# MSS_CTRL register map
Vendor: Texas Instruments
Registers are 32-bit, read-only, no defined reset value unless marked. A register's access mark holds for its fields unless they carry their own. Offsets are as the file gives them; [hi:lo] are bit positions; {n}, {i} and the like mark numbered series; 'fields as' and 'values as' point back to an identical list.

## MSS_CTRL (part 2 of 3)
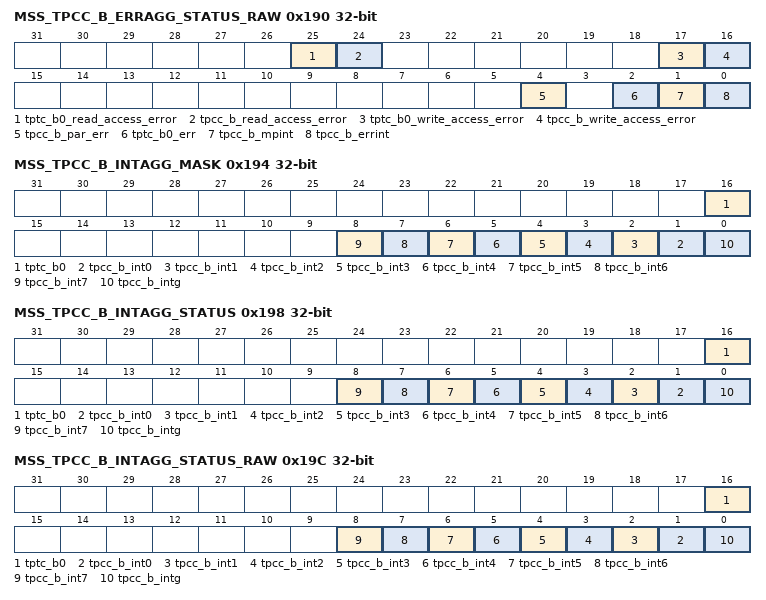
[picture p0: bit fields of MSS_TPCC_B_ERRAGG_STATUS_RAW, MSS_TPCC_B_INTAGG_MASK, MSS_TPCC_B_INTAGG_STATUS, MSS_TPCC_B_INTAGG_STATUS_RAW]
0x190 MSS_TPCC_B_ERRAGG_STATUS_RAW rw
  [25] tptc_b0_read_access_error — Raw Status of Error from MSS_TPTC_B0. Set irrespective if the Interupt is masked or unmasked in MSS_TPCC_B_ERRAGG_MASK
  [24] tpcc_b_read_access_error — Raw Status of Error from MSS_TPCC_B. Set irrespective if the Interupt is masked or unmasked in MSS_TPCC_B_ERRAGG_MASK
  [17] tptc_b0_write_access_error — Raw Status of Error from MSS_TPTC_B0. Set irrespective if the Interupt is masked or unmasked in MSS_TPCC_B_ERRAGG_MASK
  [16] tpcc_b_write_access_error — Raw Status of Error from MSS_TPCC_B. Set irrespective if the Interupt is masked or unmasked in MSS_TPCC_B_ERRAGG_MASK
  [4] tpcc_b_par_err — Raw Status of Error from MSS_TPCC_B. Set irrespective if the Interupt is masked or unmasked in MSS_TPCC_B_ERRAGG_MASK
  [2] tptc_b0_err — Raw Status of Error from MSS_TPTC_B0. Set irrespective if the Interupt is masked or unmasked in MSS_TPCC_B_ERRAGG_MASK
  [1] tpcc_b_mpint — Raw Status of Error from MSS_TPCC_B. Set irrespective if the Interupt is masked or unmasked in MSS_TPCC_B_ERRAGG_MASK
  [0] tpcc_b_errint — Raw Status of Error from MSS_TPCC_B. Set irrespective if the Interupt is masked or unmasked in MSS_TPCC_B_ERRAGG_MASK
0x194 MSS_TPCC_B_INTAGG_MASK rw
  [16] tptc_b0 — Mask Interrupt from TPTC A0 to aggregated Interrupt MSS_TPCC_A_INTAGG 1 : Interrupt is Masked 0 : Interrupt is Unmasked
  [n+1] tpcc_b_int{n} (n=0..7) — Mask Interrupt from MSS_TPCC_B to aggregated Interrupt MSS_TPCC_B_INTAGG 1 : Interrupt is Masked 0 : Interrupt is Unmasked
  [0] tpcc_b_intg — Mask Interrupt from MSS_TPCC_B to aggregated Interrupt MSS_TPCC_B_INTAGG 1 : Interrupt is Masked 0 : Interrupt is Unmasked
0x198 MSS_TPCC_B_INTAGG_STATUS rw
  [16] tptc_b0 — Status of Interrupt from TPTC A0. Set only if Interupt is unmasked in MSS_TPCC_A_INTAGG_MASK Wrie 0x1 to clear this interrupt.
  [n+1] tpcc_b_int{n} (n=0..7) — Status of Interrupt from MSS_TPCC_B. Set only if Interupt is unmasked in MSS_TPCC_B_INTAGG_MASK Wrie 0x1 to clear this interrupt.
  [0] tpcc_b_intg — Status of Interrupt from MSS_TPCC_B. Set only if Interupt is unmasked in MSS_TPCC_B_INTAGG_MASK Wrie 0x1 to clear this interrupt.
0x19C MSS_TPCC_B_INTAGG_STATUS_RAW rw
  [16] tptc_b0 — Raw Status of Interrupt from TPTC A0. Set irrespective if the Interupt is masked or unmasked in MSS_TPCC_A_INTAGG_MASK
  [n+1] tpcc_b_int{n} (n=0..7) — Raw Status of Interrupt from MSS_TPCC_B. Set irrespective if the Interupt is masked or unmasked in MSS_TPCC_C_INTAGG_MASK
  [0] tpcc_b_intg — Raw Status of Interrupt from MSS_TPCC_B. Set irrespective if the Interupt is masked or unmasked in MSS_TPCC_C_INTAGG_MASK
0x1A0 MSS_BUS_SAFETY_CTRL rw
  [2:0] enable — Refer to TPR12 Substem Microarch document for more details
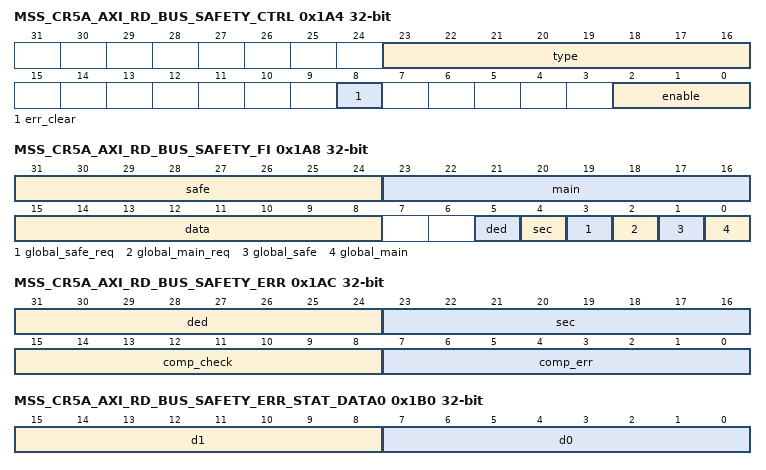
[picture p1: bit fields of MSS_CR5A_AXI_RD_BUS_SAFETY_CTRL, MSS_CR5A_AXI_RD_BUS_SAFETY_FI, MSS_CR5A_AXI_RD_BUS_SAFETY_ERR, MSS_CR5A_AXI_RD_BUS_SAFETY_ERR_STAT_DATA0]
0x1A4 MSS_CR5A_AXI_RD_BUS_SAFETY_CTRL access per field
  [23:16] type ro — Refer to TPR12 Substem Microarch document for more details
  [8] err_clear rw — Refer to TPR12 Substem Microarch document for more details
  [2:0] enable rw — Refer to TPR12 Substem Microarch document for more details
0x1A8 MSS_CR5A_AXI_RD_BUS_SAFETY_FI rw
  [31:24] safe — Refer to TPR12 Substem Microarch document for more details
  [23:16] main — Refer to TPR12 Substem Microarch document for more details
  [15:8] data — Refer to TPR12 Substem Microarch document for more details
  [5] ded — Refer to TPR12 Substem Microarch document for more details
  [4] sec — Refer to TPR12 Substem Microarch document for more details
  [3] global_safe_req — Refer to TPR12 Substem Microarch document for more details
  [2] global_main_req — Refer to TPR12 Substem Microarch document for more details
  [1] global_safe — Refer to TPR12 Substem Microarch document for more details
  [0] global_main — Refer to TPR12 Substem Microarch document for more details
0x1AC MSS_CR5A_AXI_RD_BUS_SAFETY_ERR
  [31:24] ded — Refer to TPR12 Substem Microarch document for more details
  [23:16] sec — Refer to TPR12 Substem Microarch document for more details
  [15:8] comp_check — Refer to TPR12 Substem Microarch document for more details
  [7:0] comp_err — Refer to TPR12 Substem Microarch document for more details
0x1B0 MSS_CR5A_AXI_RD_BUS_SAFETY_ERR_STAT_DATA0
  [15:8] d1 — Refer to TPR12 Substem Microarch document for more details
  [7:0] d0 — Refer to TPR12 Substem Microarch document for more details
0x1B4 MSS_CR5A_AXI_RD_BUS_SAFETY_ERR_STAT_CMD
  [31:0] stat — Refer to TPR12 Substem Microarch document for more details
0x1B8 MSS_CR5A_AXI_RD_BUS_SAFETY_ERR_STAT_READ
  fields as MSS_CR5A_AXI_RD_BUS_SAFETY_ERR_STAT_CMD
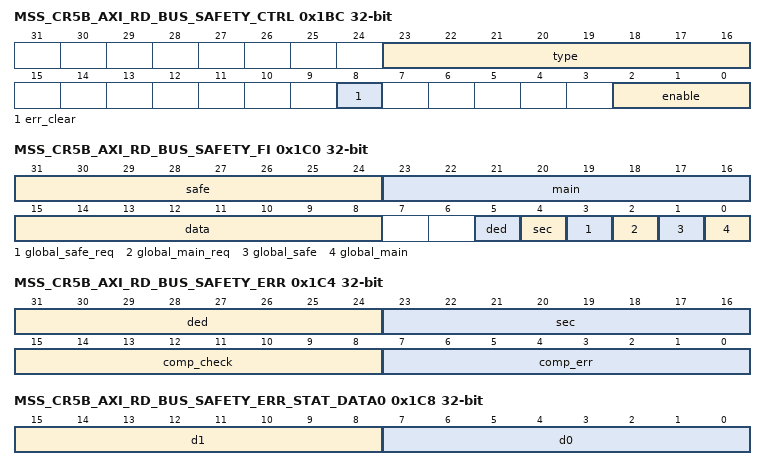
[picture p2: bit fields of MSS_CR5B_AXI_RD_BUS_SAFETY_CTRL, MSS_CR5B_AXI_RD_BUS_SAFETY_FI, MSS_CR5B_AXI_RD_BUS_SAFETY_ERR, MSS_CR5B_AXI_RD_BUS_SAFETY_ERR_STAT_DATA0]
0x1BC MSS_CR5B_AXI_RD_BUS_SAFETY_CTRL access per field
  fields as MSS_CR5A_AXI_RD_BUS_SAFETY_CTRL
0x1C0 MSS_CR5B_AXI_RD_BUS_SAFETY_FI rw
  fields as MSS_CR5A_AXI_RD_BUS_SAFETY_FI
0x1C4 MSS_CR5B_AXI_RD_BUS_SAFETY_ERR
  fields as MSS_CR5A_AXI_RD_BUS_SAFETY_ERR
0x1C8 MSS_CR5B_AXI_RD_BUS_SAFETY_ERR_STAT_DATA0
  fields as MSS_CR5A_AXI_RD_BUS_SAFETY_ERR_STAT_DATA0
0x1CC MSS_CR5B_AXI_RD_BUS_SAFETY_ERR_STAT_CMD
  fields as MSS_CR5A_AXI_RD_BUS_SAFETY_ERR_STAT_CMD
0x1D0 MSS_CR5B_AXI_RD_BUS_SAFETY_ERR_STAT_READ
  fields as MSS_CR5A_AXI_RD_BUS_SAFETY_ERR_STAT_CMD
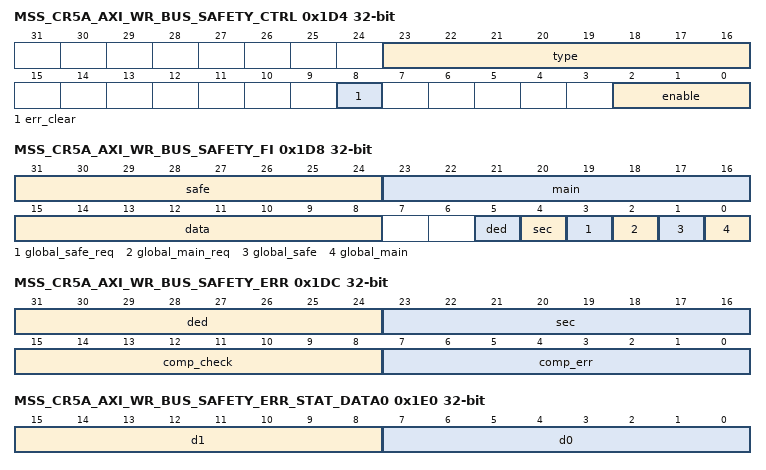
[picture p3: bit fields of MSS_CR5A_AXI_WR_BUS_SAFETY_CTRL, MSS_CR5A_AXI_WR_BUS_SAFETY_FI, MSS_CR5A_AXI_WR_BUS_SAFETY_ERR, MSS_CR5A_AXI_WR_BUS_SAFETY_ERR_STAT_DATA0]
0x1D4 MSS_CR5A_AXI_WR_BUS_SAFETY_CTRL access per field
  fields as MSS_CR5A_AXI_RD_BUS_SAFETY_CTRL
0x1D8 MSS_CR5A_AXI_WR_BUS_SAFETY_FI rw
  fields as MSS_CR5A_AXI_RD_BUS_SAFETY_FI
0x1DC MSS_CR5A_AXI_WR_BUS_SAFETY_ERR
  fields as MSS_CR5A_AXI_RD_BUS_SAFETY_ERR
0x1E0 MSS_CR5A_AXI_WR_BUS_SAFETY_ERR_STAT_DATA0
  fields as MSS_CR5A_AXI_RD_BUS_SAFETY_ERR_STAT_DATA0
0x1E4 MSS_CR5A_AXI_WR_BUS_SAFETY_ERR_STAT_CMD
  fields as MSS_CR5A_AXI_RD_BUS_SAFETY_ERR_STAT_CMD
0x1E8 MSS_CR5A_AXI_WR_BUS_SAFETY_ERR_STAT_WRITE
  fields as MSS_CR5A_AXI_RD_BUS_SAFETY_ERR_STAT_CMD
0x1EC MSS_CR5A_AXI_WR_BUS_SAFETY_ERR_STAT_WRITERESP
  fields as MSS_CR5A_AXI_RD_BUS_SAFETY_ERR_STAT_CMD
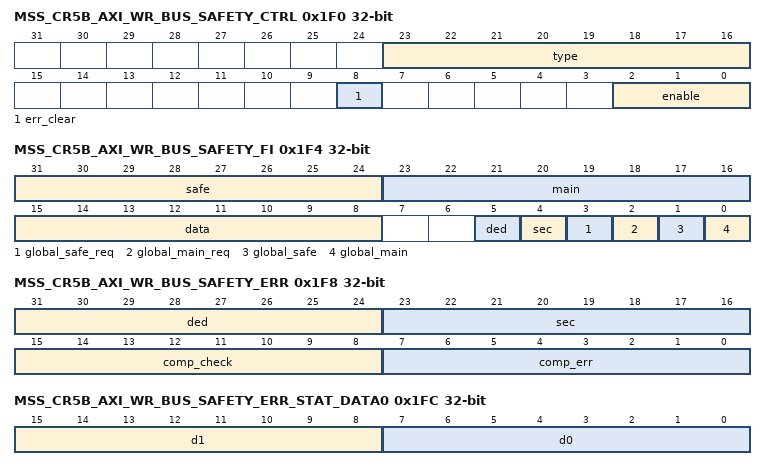
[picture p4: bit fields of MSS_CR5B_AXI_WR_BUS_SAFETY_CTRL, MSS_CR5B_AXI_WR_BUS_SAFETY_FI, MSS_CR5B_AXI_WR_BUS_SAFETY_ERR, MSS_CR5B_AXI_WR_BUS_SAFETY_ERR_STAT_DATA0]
0x1F0 MSS_CR5B_AXI_WR_BUS_SAFETY_CTRL access per field
  fields as MSS_CR5A_AXI_RD_BUS_SAFETY_CTRL
0x1F4 MSS_CR5B_AXI_WR_BUS_SAFETY_FI rw
  fields as MSS_CR5A_AXI_RD_BUS_SAFETY_FI
0x1F8 MSS_CR5B_AXI_WR_BUS_SAFETY_ERR
  fields as MSS_CR5A_AXI_RD_BUS_SAFETY_ERR
0x1FC MSS_CR5B_AXI_WR_BUS_SAFETY_ERR_STAT_DATA0
  fields as MSS_CR5A_AXI_RD_BUS_SAFETY_ERR_STAT_DATA0
0x200 MSS_CR5B_AXI_WR_BUS_SAFETY_ERR_STAT_CMD
  fields as MSS_CR5A_AXI_RD_BUS_SAFETY_ERR_STAT_CMD
0x204 MSS_CR5B_AXI_WR_BUS_SAFETY_ERR_STAT_WRITE
  fields as MSS_CR5A_AXI_RD_BUS_SAFETY_ERR_STAT_CMD
0x208 MSS_CR5B_AXI_WR_BUS_SAFETY_ERR_STAT_WRITERESP
  fields as MSS_CR5A_AXI_RD_BUS_SAFETY_ERR_STAT_CMD
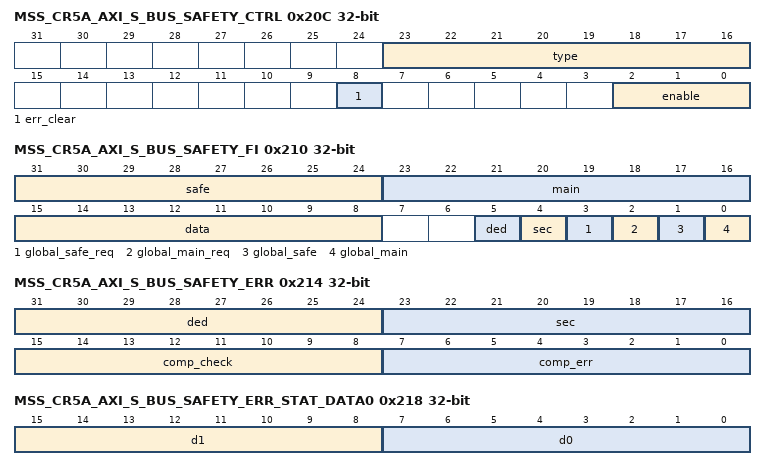
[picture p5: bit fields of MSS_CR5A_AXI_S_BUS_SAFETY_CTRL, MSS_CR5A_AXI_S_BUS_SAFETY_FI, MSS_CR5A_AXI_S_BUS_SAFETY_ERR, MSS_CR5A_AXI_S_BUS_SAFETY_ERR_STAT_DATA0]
0x20C MSS_CR5A_AXI_S_BUS_SAFETY_CTRL access per field
  fields as MSS_CR5A_AXI_RD_BUS_SAFETY_CTRL
0x210 MSS_CR5A_AXI_S_BUS_SAFETY_FI rw
  fields as MSS_CR5A_AXI_RD_BUS_SAFETY_FI
0x214 MSS_CR5A_AXI_S_BUS_SAFETY_ERR
  fields as MSS_CR5A_AXI_RD_BUS_SAFETY_ERR
0x218 MSS_CR5A_AXI_S_BUS_SAFETY_ERR_STAT_DATA0
  fields as MSS_CR5A_AXI_RD_BUS_SAFETY_ERR_STAT_DATA0
0x21C MSS_CR5A_AXI_S_BUS_SAFETY_ERR_STAT_CMD
  fields as MSS_CR5A_AXI_RD_BUS_SAFETY_ERR_STAT_CMD
0x220 MSS_CR5A_AXI_S_BUS_SAFETY_ERR_STAT_WRITE
  fields as MSS_CR5A_AXI_RD_BUS_SAFETY_ERR_STAT_CMD
0x224 MSS_CR5A_AXI_S_BUS_SAFETY_ERR_STAT_READ
  fields as MSS_CR5A_AXI_RD_BUS_SAFETY_ERR_STAT_CMD
0x228 MSS_CR5A_AXI_S_BUS_SAFETY_ERR_STAT_WRITERESP
  fields as MSS_CR5A_AXI_RD_BUS_SAFETY_ERR_STAT_CMD
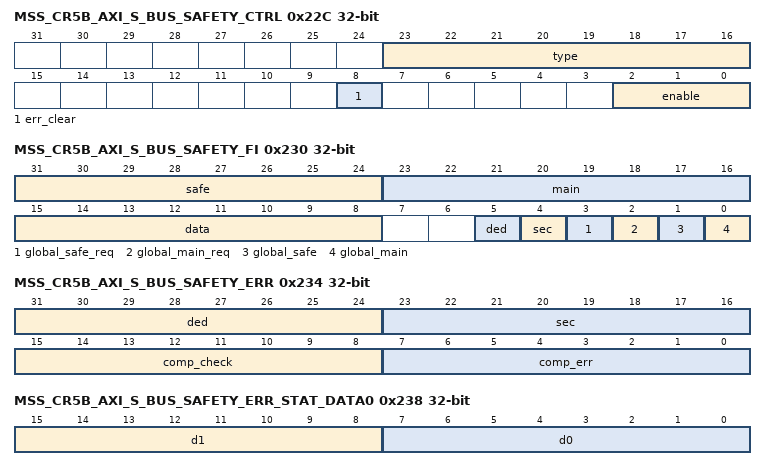
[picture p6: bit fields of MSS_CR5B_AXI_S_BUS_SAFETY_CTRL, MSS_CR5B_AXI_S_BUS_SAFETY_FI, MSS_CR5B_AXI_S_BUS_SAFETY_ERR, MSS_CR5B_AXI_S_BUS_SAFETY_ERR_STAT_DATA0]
0x22C MSS_CR5B_AXI_S_BUS_SAFETY_CTRL access per field
  fields as MSS_CR5A_AXI_RD_BUS_SAFETY_CTRL
0x230 MSS_CR5B_AXI_S_BUS_SAFETY_FI rw
  fields as MSS_CR5A_AXI_RD_BUS_SAFETY_FI
0x234 MSS_CR5B_AXI_S_BUS_SAFETY_ERR
  fields as MSS_CR5A_AXI_RD_BUS_SAFETY_ERR
0x238 MSS_CR5B_AXI_S_BUS_SAFETY_ERR_STAT_DATA0
  fields as MSS_CR5A_AXI_RD_BUS_SAFETY_ERR_STAT_DATA0
0x23C MSS_CR5B_AXI_S_BUS_SAFETY_ERR_STAT_CMD
  fields as MSS_CR5A_AXI_RD_BUS_SAFETY_ERR_STAT_CMD
0x240 MSS_CR5B_AXI_S_BUS_SAFETY_ERR_STAT_WRITE
  fields as MSS_CR5A_AXI_RD_BUS_SAFETY_ERR_STAT_CMD
0x244 MSS_CR5B_AXI_S_BUS_SAFETY_ERR_STAT_READ
  fields as MSS_CR5A_AXI_RD_BUS_SAFETY_ERR_STAT_CMD
0x248 MSS_CR5B_AXI_S_BUS_SAFETY_ERR_STAT_WRITERESP
  fields as MSS_CR5A_AXI_RD_BUS_SAFETY_ERR_STAT_CMD
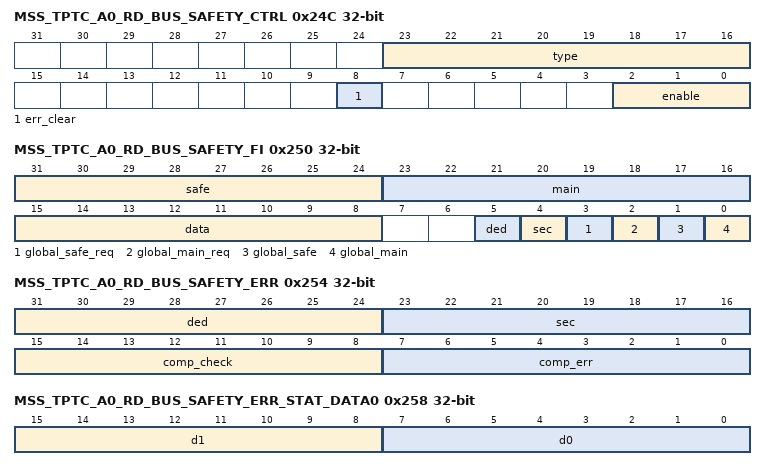
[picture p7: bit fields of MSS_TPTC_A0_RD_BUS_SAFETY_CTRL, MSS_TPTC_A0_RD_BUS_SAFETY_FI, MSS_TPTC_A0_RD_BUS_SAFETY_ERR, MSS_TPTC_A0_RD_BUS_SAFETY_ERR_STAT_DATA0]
0x24C MSS_TPTC_A0_RD_BUS_SAFETY_CTRL access per field
  fields as MSS_CR5A_AXI_RD_BUS_SAFETY_CTRL
0x250 MSS_TPTC_A0_RD_BUS_SAFETY_FI rw
  fields as MSS_CR5A_AXI_RD_BUS_SAFETY_FI
0x254 MSS_TPTC_A0_RD_BUS_SAFETY_ERR
  fields as MSS_CR5A_AXI_RD_BUS_SAFETY_ERR
0x258 MSS_TPTC_A0_RD_BUS_SAFETY_ERR_STAT_DATA0
  fields as MSS_CR5A_AXI_RD_BUS_SAFETY_ERR_STAT_DATA0
0x25C MSS_TPTC_A0_RD_BUS_SAFETY_ERR_STAT_CMD
  fields as MSS_CR5A_AXI_RD_BUS_SAFETY_ERR_STAT_CMD
0x260 MSS_TPTC_A0_RD_BUS_SAFETY_ERR_STAT_READ
  fields as MSS_CR5A_AXI_RD_BUS_SAFETY_ERR_STAT_CMD
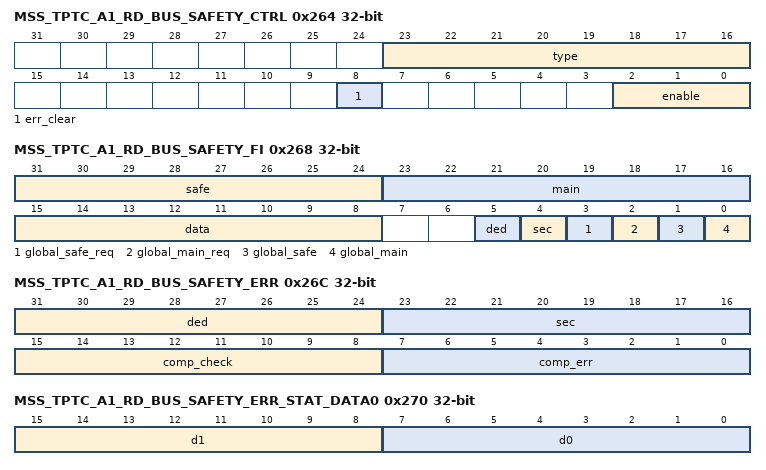
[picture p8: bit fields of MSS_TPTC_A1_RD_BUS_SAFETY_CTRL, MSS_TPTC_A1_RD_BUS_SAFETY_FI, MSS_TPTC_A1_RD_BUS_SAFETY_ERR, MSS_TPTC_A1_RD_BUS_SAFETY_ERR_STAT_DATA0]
0x264 MSS_TPTC_A1_RD_BUS_SAFETY_CTRL access per field
  fields as MSS_CR5A_AXI_RD_BUS_SAFETY_CTRL
0x268 MSS_TPTC_A1_RD_BUS_SAFETY_FI rw
  fields as MSS_CR5A_AXI_RD_BUS_SAFETY_FI
0x26C MSS_TPTC_A1_RD_BUS_SAFETY_ERR
  fields as MSS_CR5A_AXI_RD_BUS_SAFETY_ERR
0x270 MSS_TPTC_A1_RD_BUS_SAFETY_ERR_STAT_DATA0
  fields as MSS_CR5A_AXI_RD_BUS_SAFETY_ERR_STAT_DATA0
0x274 MSS_TPTC_A1_RD_BUS_SAFETY_ERR_STAT_CMD
  fields as MSS_CR5A_AXI_RD_BUS_SAFETY_ERR_STAT_CMD
0x278 MSS_TPTC_A1_RD_BUS_SAFETY_ERR_STAT_READ
  fields as MSS_CR5A_AXI_RD_BUS_SAFETY_ERR_STAT_CMD
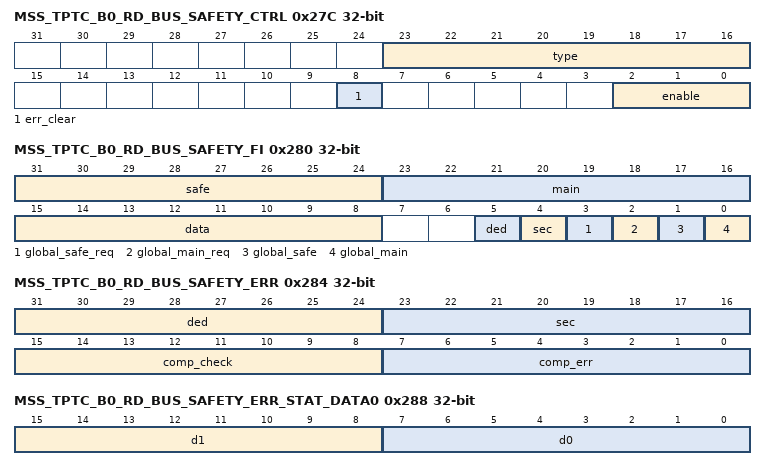
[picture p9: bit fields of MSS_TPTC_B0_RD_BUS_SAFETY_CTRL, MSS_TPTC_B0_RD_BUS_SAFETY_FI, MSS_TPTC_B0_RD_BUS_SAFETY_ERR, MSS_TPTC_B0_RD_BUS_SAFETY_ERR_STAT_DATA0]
0x27C MSS_TPTC_B0_RD_BUS_SAFETY_CTRL access per field
  fields as MSS_CR5A_AXI_RD_BUS_SAFETY_CTRL
0x280 MSS_TPTC_B0_RD_BUS_SAFETY_FI rw
  fields as MSS_CR5A_AXI_RD_BUS_SAFETY_FI
0x284 MSS_TPTC_B0_RD_BUS_SAFETY_ERR
  fields as MSS_CR5A_AXI_RD_BUS_SAFETY_ERR
0x288 MSS_TPTC_B0_RD_BUS_SAFETY_ERR_STAT_DATA0
  fields as MSS_CR5A_AXI_RD_BUS_SAFETY_ERR_STAT_DATA0
0x28C MSS_TPTC_B0_RD_BUS_SAFETY_ERR_STAT_CMD
  fields as MSS_CR5A_AXI_RD_BUS_SAFETY_ERR_STAT_CMD
0x290 MSS_TPTC_B0_RD_BUS_SAFETY_ERR_STAT_READ
  fields as MSS_CR5A_AXI_RD_BUS_SAFETY_ERR_STAT_CMD
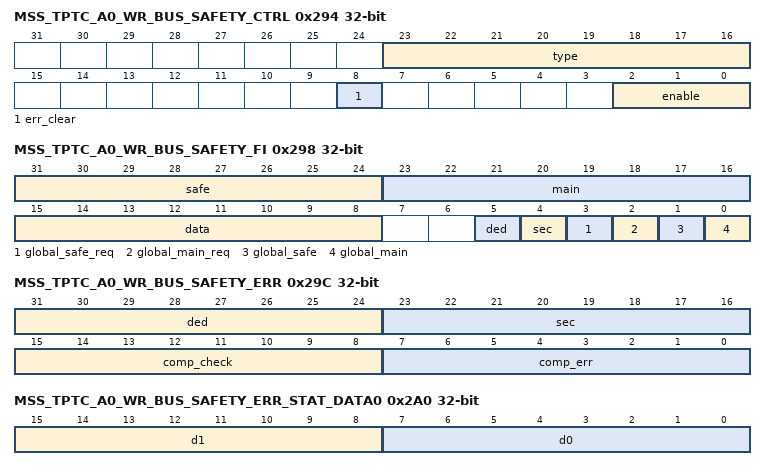
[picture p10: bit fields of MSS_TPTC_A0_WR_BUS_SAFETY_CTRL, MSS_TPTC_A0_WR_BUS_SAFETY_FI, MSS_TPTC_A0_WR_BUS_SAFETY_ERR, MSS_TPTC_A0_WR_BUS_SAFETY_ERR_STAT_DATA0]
0x294 MSS_TPTC_A0_WR_BUS_SAFETY_CTRL access per field
  fields as MSS_CR5A_AXI_RD_BUS_SAFETY_CTRL
0x298 MSS_TPTC_A0_WR_BUS_SAFETY_FI rw
  fields as MSS_CR5A_AXI_RD_BUS_SAFETY_FI
0x29C MSS_TPTC_A0_WR_BUS_SAFETY_ERR
  fields as MSS_CR5A_AXI_RD_BUS_SAFETY_ERR
0x2A0 MSS_TPTC_A0_WR_BUS_SAFETY_ERR_STAT_DATA0
  fields as MSS_CR5A_AXI_RD_BUS_SAFETY_ERR_STAT_DATA0
0x2A4 MSS_TPTC_A0_WR_BUS_SAFETY_ERR_STAT_CMD
  fields as MSS_CR5A_AXI_RD_BUS_SAFETY_ERR_STAT_CMD
0x2A8 MSS_TPTC_A0_WR_BUS_SAFETY_ERR_STAT_WRITE
  fields as MSS_CR5A_AXI_RD_BUS_SAFETY_ERR_STAT_CMD
0x2AC MSS_TPTC_A0_WR_BUS_SAFETY_ERR_STAT_WRITERESP
  fields as MSS_CR5A_AXI_RD_BUS_SAFETY_ERR_STAT_CMD
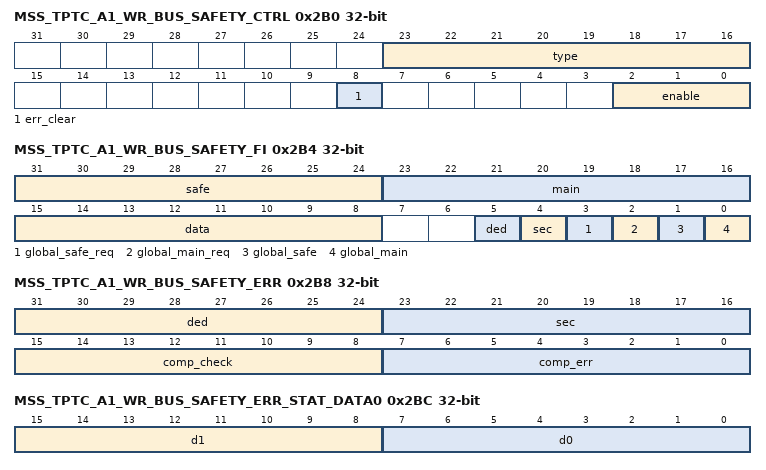
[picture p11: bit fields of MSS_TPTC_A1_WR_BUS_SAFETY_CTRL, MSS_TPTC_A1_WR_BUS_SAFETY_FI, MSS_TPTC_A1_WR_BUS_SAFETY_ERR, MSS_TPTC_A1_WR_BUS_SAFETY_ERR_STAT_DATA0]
0x2B0 MSS_TPTC_A1_WR_BUS_SAFETY_CTRL access per field
  fields as MSS_CR5A_AXI_RD_BUS_SAFETY_CTRL
0x2B4 MSS_TPTC_A1_WR_BUS_SAFETY_FI rw
  fields as MSS_CR5A_AXI_RD_BUS_SAFETY_FI
0x2B8 MSS_TPTC_A1_WR_BUS_SAFETY_ERR
  fields as MSS_CR5A_AXI_RD_BUS_SAFETY_ERR
0x2BC MSS_TPTC_A1_WR_BUS_SAFETY_ERR_STAT_DATA0
  fields as MSS_CR5A_AXI_RD_BUS_SAFETY_ERR_STAT_DATA0
0x2C0 MSS_TPTC_A1_WR_BUS_SAFETY_ERR_STAT_CMD
  fields as MSS_CR5A_AXI_RD_BUS_SAFETY_ERR_STAT_CMD
0x2C4 MSS_TPTC_A1_WR_BUS_SAFETY_ERR_STAT_WRITE
  fields as MSS_CR5A_AXI_RD_BUS_SAFETY_ERR_STAT_CMD
0x2C8 MSS_TPTC_A1_WR_BUS_SAFETY_ERR_STAT_WRITERESP
  fields as MSS_CR5A_AXI_RD_BUS_SAFETY_ERR_STAT_CMD
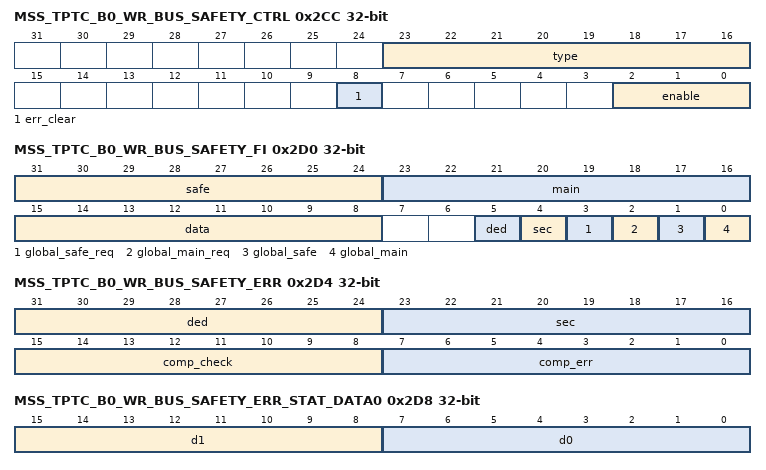
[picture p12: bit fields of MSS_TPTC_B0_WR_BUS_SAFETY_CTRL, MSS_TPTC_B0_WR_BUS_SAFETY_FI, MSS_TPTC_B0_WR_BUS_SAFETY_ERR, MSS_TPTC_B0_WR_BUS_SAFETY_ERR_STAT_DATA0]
0x2CC MSS_TPTC_B0_WR_BUS_SAFETY_CTRL access per field
  fields as MSS_CR5A_AXI_RD_BUS_SAFETY_CTRL
0x2D0 MSS_TPTC_B0_WR_BUS_SAFETY_FI rw
  fields as MSS_CR5A_AXI_RD_BUS_SAFETY_FI
0x2D4 MSS_TPTC_B0_WR_BUS_SAFETY_ERR
  fields as MSS_CR5A_AXI_RD_BUS_SAFETY_ERR
0x2D8 MSS_TPTC_B0_WR_BUS_SAFETY_ERR_STAT_DATA0
  fields as MSS_CR5A_AXI_RD_BUS_SAFETY_ERR_STAT_DATA0
0x2DC MSS_TPTC_B0_WR_BUS_SAFETY_ERR_STAT_CMD
  fields as MSS_CR5A_AXI_RD_BUS_SAFETY_ERR_STAT_CMD
0x2E0 MSS_TPTC_B0_WR_BUS_SAFETY_ERR_STAT_WRITE
  fields as MSS_CR5A_AXI_RD_BUS_SAFETY_ERR_STAT_CMD
0x2E4 MSS_TPTC_B0_WR_BUS_SAFETY_ERR_STAT_WRITERESP
  fields as MSS_CR5A_AXI_RD_BUS_SAFETY_ERR_STAT_CMD
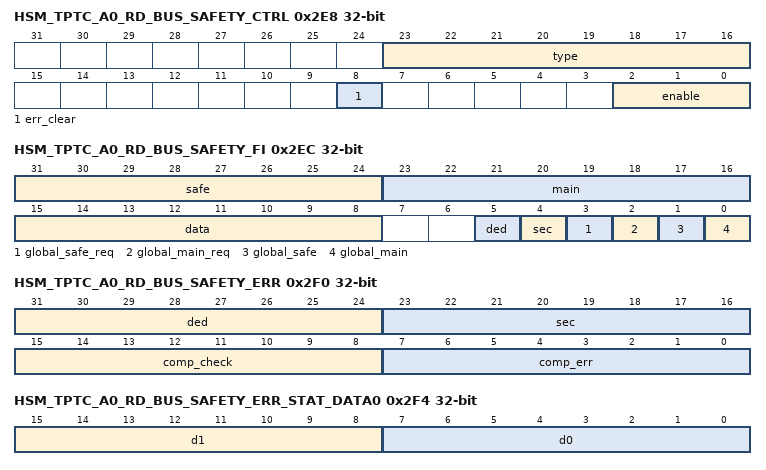
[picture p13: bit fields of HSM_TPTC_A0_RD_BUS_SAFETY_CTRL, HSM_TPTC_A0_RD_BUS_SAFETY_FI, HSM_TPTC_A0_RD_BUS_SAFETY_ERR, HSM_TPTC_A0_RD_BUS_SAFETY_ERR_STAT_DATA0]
0x2E8 HSM_TPTC_A0_RD_BUS_SAFETY_CTRL access per field
  fields as MSS_CR5A_AXI_RD_BUS_SAFETY_CTRL
0x2EC HSM_TPTC_A0_RD_BUS_SAFETY_FI rw
  fields as MSS_CR5A_AXI_RD_BUS_SAFETY_FI
0x2F0 HSM_TPTC_A0_RD_BUS_SAFETY_ERR
  fields as MSS_CR5A_AXI_RD_BUS_SAFETY_ERR
0x2F4 HSM_TPTC_A0_RD_BUS_SAFETY_ERR_STAT_DATA0
  fields as MSS_CR5A_AXI_RD_BUS_SAFETY_ERR_STAT_DATA0
0x2F8 HSM_TPTC_A0_RD_BUS_SAFETY_ERR_STAT_CMD
  fields as MSS_CR5A_AXI_RD_BUS_SAFETY_ERR_STAT_CMD
0x2FC HSM_TPTC_A0_RD_BUS_SAFETY_ERR_STAT_READ
  fields as MSS_CR5A_AXI_RD_BUS_SAFETY_ERR_STAT_CMD
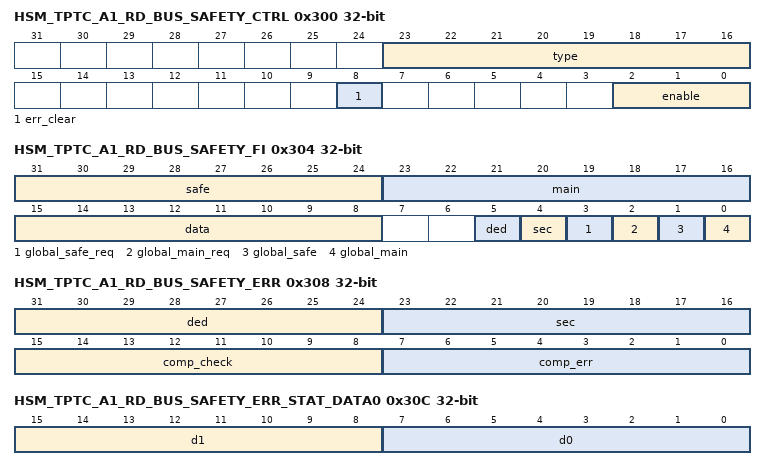
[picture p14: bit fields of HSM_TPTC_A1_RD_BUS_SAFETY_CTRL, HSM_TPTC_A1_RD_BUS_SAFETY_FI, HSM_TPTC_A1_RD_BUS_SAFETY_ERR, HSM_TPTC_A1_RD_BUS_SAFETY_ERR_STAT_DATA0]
0x300 HSM_TPTC_A1_RD_BUS_SAFETY_CTRL access per field
  fields as MSS_CR5A_AXI_RD_BUS_SAFETY_CTRL
0x304 HSM_TPTC_A1_RD_BUS_SAFETY_FI rw
  fields as MSS_CR5A_AXI_RD_BUS_SAFETY_FI
0x308 HSM_TPTC_A1_RD_BUS_SAFETY_ERR
  fields as MSS_CR5A_AXI_RD_BUS_SAFETY_ERR
0x30C HSM_TPTC_A1_RD_BUS_SAFETY_ERR_STAT_DATA0
  fields as MSS_CR5A_AXI_RD_BUS_SAFETY_ERR_STAT_DATA0
0x310 HSM_TPTC_A1_RD_BUS_SAFETY_ERR_STAT_CMD
  fields as MSS_CR5A_AXI_RD_BUS_SAFETY_ERR_STAT_CMD
0x314 HSM_TPTC_A1_RD_BUS_SAFETY_ERR_STAT_READ
  fields as MSS_CR5A_AXI_RD_BUS_SAFETY_ERR_STAT_CMD
0x318 HSM_TPTC_A0_WR_BUS_SAFETY_CTRL access per field
  fields as MSS_CR5A_AXI_RD_BUS_SAFETY_CTRL
0x31C HSM_TPTC_A0_WR_BUS_SAFETY_FI rw
  fields as MSS_CR5A_AXI_RD_BUS_SAFETY_FI
0x320 HSM_TPTC_A0_WR_BUS_SAFETY_ERR
  fields as MSS_CR5A_AXI_RD_BUS_SAFETY_ERR
0x324 HSM_TPTC_A0_WR_BUS_SAFETY_ERR_STAT_DATA0
  fields as MSS_CR5A_AXI_RD_BUS_SAFETY_ERR_STAT_DATA0
0x328 HSM_TPTC_A0_WR_BUS_SAFETY_ERR_STAT_CMD
  fields as MSS_CR5A_AXI_RD_BUS_SAFETY_ERR_STAT_CMD
0x32C HSM_TPTC_A0_WR_BUS_SAFETY_ERR_STAT_WRITE
  fields as MSS_CR5A_AXI_RD_BUS_SAFETY_ERR_STAT_CMD
0x330 HSM_TPTC_A0_WR_BUS_SAFETY_ERR_STAT_WRITERESP
  fields as MSS_CR5A_AXI_RD_BUS_SAFETY_ERR_STAT_CMD
0x334 HSM_TPTC_A1_WR_BUS_SAFETY_CTRL access per field
  fields as MSS_CR5A_AXI_RD_BUS_SAFETY_CTRL
0x338 HSM_TPTC_A1_WR_BUS_SAFETY_FI rw
  fields as MSS_CR5A_AXI_RD_BUS_SAFETY_FI
0x33C HSM_TPTC_A1_WR_BUS_SAFETY_ERR
  fields as MSS_CR5A_AXI_RD_BUS_SAFETY_ERR
0x340 HSM_TPTC_A1_WR_BUS_SAFETY_ERR_STAT_DATA0
  fields as MSS_CR5A_AXI_RD_BUS_SAFETY_ERR_STAT_DATA0
0x344 HSM_TPTC_A1_WR_BUS_SAFETY_ERR_STAT_CMD
  fields as MSS_CR5A_AXI_RD_BUS_SAFETY_ERR_STAT_CMD
0x348 HSM_TPTC_A1_WR_BUS_SAFETY_ERR_STAT_WRITE
  fields as MSS_CR5A_AXI_RD_BUS_SAFETY_ERR_STAT_CMD
0x34C HSM_TPTC_A1_WR_BUS_SAFETY_ERR_STAT_WRITERESP
  fields as MSS_CR5A_AXI_RD_BUS_SAFETY_ERR_STAT_CMD
0x350 MSS_QSPI_BUS_SAFETY_CTRL access per field
  fields as MSS_CR5A_AXI_RD_BUS_SAFETY_CTRL
0x354 MSS_QSPI_BUS_SAFETY_FI rw
  fields as MSS_CR5A_AXI_RD_BUS_SAFETY_FI
0x358 MSS_QSPI_BUS_SAFETY_ERR
  fields as MSS_CR5A_AXI_RD_BUS_SAFETY_ERR
0x35C MSS_QSPI_BUS_SAFETY_ERR_STAT_DATA0
  fields as MSS_CR5A_AXI_RD_BUS_SAFETY_ERR_STAT_DATA0
0x360 MSS_QSPI_BUS_SAFETY_ERR_STAT_CMD
  fields as MSS_CR5A_AXI_RD_BUS_SAFETY_ERR_STAT_CMD
0x364 MSS_QSPI_BUS_SAFETY_ERR_STAT_WRITE
  fields as MSS_CR5A_AXI_RD_BUS_SAFETY_ERR_STAT_CMD
0x368 MSS_QSPI_BUS_SAFETY_ERR_STAT_READ
  fields as MSS_CR5A_AXI_RD_BUS_SAFETY_ERR_STAT_CMD
0x36C MSS_QSPI_BUS_SAFETY_ERR_STAT_WRITERESP
  fields as MSS_CR5A_AXI_RD_BUS_SAFETY_ERR_STAT_CMD
0x370 HSM_DTHE_BUS_SAFETY_CTRL access per field
  fields as MSS_CR5A_AXI_RD_BUS_SAFETY_CTRL
0x374 HSM_DTHE_BUS_SAFETY_FI rw
  fields as MSS_CR5A_AXI_RD_BUS_SAFETY_FI
0x378 HSM_DTHE_BUS_SAFETY_ERR
  fields as MSS_CR5A_AXI_RD_BUS_SAFETY_ERR
0x37C HSM_DTHE_BUS_SAFETY_ERR_STAT_DATA0
  fields as MSS_CR5A_AXI_RD_BUS_SAFETY_ERR_STAT_DATA0
0x380 HSM_DTHE_BUS_SAFETY_ERR_STAT_CMD
  fields as MSS_CR5A_AXI_RD_BUS_SAFETY_ERR_STAT_CMD
0x384 HSM_DTHE_BUS_SAFETY_ERR_STAT_WRITE
  fields as MSS_CR5A_AXI_RD_BUS_SAFETY_ERR_STAT_CMD
0x388 HSM_DTHE_BUS_SAFETY_ERR_STAT_READ
  fields as MSS_CR5A_AXI_RD_BUS_SAFETY_ERR_STAT_CMD
0x38C HSM_DTHE_BUS_SAFETY_ERR_STAT_WRITERESP
  fields as MSS_CR5A_AXI_RD_BUS_SAFETY_ERR_STAT_CMD
0x390 MSS_CPSW_BUS_SAFETY_CTRL access per field
  fields as MSS_CR5A_AXI_RD_BUS_SAFETY_CTRL
0x394 MSS_CPSW_BUS_SAFETY_FI rw
  fields as MSS_CR5A_AXI_RD_BUS_SAFETY_FI
0x398 MSS_CPSW_BUS_SAFETY_ERR
  fields as MSS_CR5A_AXI_RD_BUS_SAFETY_ERR
0x39C MSS_CPSW_BUS_SAFETY_ERR_STAT_DATA0
  fields as MSS_CR5A_AXI_RD_BUS_SAFETY_ERR_STAT_DATA0
0x3A0 MSS_CPSW_BUS_SAFETY_ERR_STAT_CMD
  fields as MSS_CR5A_AXI_RD_BUS_SAFETY_ERR_STAT_CMD
0x3A4 MSS_CPSW_BUS_SAFETY_ERR_STAT_WRITE
  fields as MSS_CR5A_AXI_RD_BUS_SAFETY_ERR_STAT_CMD
0x3A8 MSS_CPSW_BUS_SAFETY_ERR_STAT_READ
  fields as MSS_CR5A_AXI_RD_BUS_SAFETY_ERR_STAT_CMD
0x3AC MSS_CPSW_BUS_SAFETY_ERR_STAT_WRITERESP
  fields as MSS_CR5A_AXI_RD_BUS_SAFETY_ERR_STAT_CMD
0x3B0 MSS_MCRC_BUS_SAFETY_CTRL access per field
  fields as MSS_CR5A_AXI_RD_BUS_SAFETY_CTRL
0x3B4 MSS_MCRC_BUS_SAFETY_FI rw
  fields as MSS_CR5A_AXI_RD_BUS_SAFETY_FI
0x3B8 MSS_MCRC_BUS_SAFETY_ERR
  fields as MSS_CR5A_AXI_RD_BUS_SAFETY_ERR
0x3BC MSS_MCRC_BUS_SAFETY_ERR_STAT_DATA0
  fields as MSS_CR5A_AXI_RD_BUS_SAFETY_ERR_STAT_DATA0
0x3C0 MSS_MCRC_BUS_SAFETY_ERR_STAT_CMD
  fields as MSS_CR5A_AXI_RD_BUS_SAFETY_ERR_STAT_CMD
0x3C4 MSS_MCRC_BUS_SAFETY_ERR_STAT_WRITE
  fields as MSS_CR5A_AXI_RD_BUS_SAFETY_ERR_STAT_CMD
0x3C8 MSS_MCRC_BUS_SAFETY_ERR_STAT_READ
  fields as MSS_CR5A_AXI_RD_BUS_SAFETY_ERR_STAT_CMD
0x3CC MSS_MCRC_BUS_SAFETY_ERR_STAT_WRITERESP
  fields as MSS_CR5A_AXI_RD_BUS_SAFETY_ERR_STAT_CMD
0x3D0 MSS_PCR_BUS_SAFETY_CTRL access per field
  fields as MSS_CR5A_AXI_RD_BUS_SAFETY_CTRL
0x3D4 MSS_PCR_BUS_SAFETY_FI rw
  fields as MSS_CR5A_AXI_RD_BUS_SAFETY_FI
0x3D8 MSS_PCR_BUS_SAFETY_ERR
  fields as MSS_CR5A_AXI_RD_BUS_SAFETY_ERR
0x3DC MSS_PCR_BUS_SAFETY_ERR_STAT_DATA0
  fields as MSS_CR5A_AXI_RD_BUS_SAFETY_ERR_STAT_DATA0
0x3E0 MSS_PCR_BUS_SAFETY_ERR_STAT_CMD
  fields as MSS_CR5A_AXI_RD_BUS_SAFETY_ERR_STAT_CMD
0x3E4 MSS_PCR_BUS_SAFETY_ERR_STAT_WRITE
  fields as MSS_CR5A_AXI_RD_BUS_SAFETY_ERR_STAT_CMD
0x3E8 MSS_PCR_BUS_SAFETY_ERR_STAT_READ
  fields as MSS_CR5A_AXI_RD_BUS_SAFETY_ERR_STAT_CMD
0x3EC MSS_PCR_BUS_SAFETY_ERR_STAT_WRITERESP
  fields as MSS_CR5A_AXI_RD_BUS_SAFETY_ERR_STAT_CMD
0x3F0 MSS_PCR2_BUS_SAFETY_CTRL access per field
  fields as MSS_CR5A_AXI_RD_BUS_SAFETY_CTRL
0x3F4 MSS_PCR2_BUS_SAFETY_FI rw
  fields as MSS_CR5A_AXI_RD_BUS_SAFETY_FI
0x3F8 MSS_PCR2_BUS_SAFETY_ERR
  fields as MSS_CR5A_AXI_RD_BUS_SAFETY_ERR
0x3FC MSS_PCR2_BUS_SAFETY_ERR_STAT_DATA0
  fields as MSS_CR5A_AXI_RD_BUS_SAFETY_ERR_STAT_DATA0
0x400 MSS_PCR2_BUS_SAFETY_ERR_STAT_CMD
  fields as MSS_CR5A_AXI_RD_BUS_SAFETY_ERR_STAT_CMD
0x404 MSS_PCR2_BUS_SAFETY_ERR_STAT_WRITE
  fields as MSS_CR5A_AXI_RD_BUS_SAFETY_ERR_STAT_CMD
0x408 MSS_PCR2_BUS_SAFETY_ERR_STAT_READ
  fields as MSS_CR5A_AXI_RD_BUS_SAFETY_ERR_STAT_CMD
0x40C MSS_PCR2_BUS_SAFETY_ERR_STAT_WRITERESP
  fields as MSS_CR5A_AXI_RD_BUS_SAFETY_ERR_STAT_CMD
0x410 HSM_M_BUS_SAFETY_CTRL access per field
  fields as MSS_CR5A_AXI_RD_BUS_SAFETY_CTRL
0x414 HSM_M_BUS_SAFETY_FI rw
  fields as MSS_CR5A_AXI_RD_BUS_SAFETY_FI
0x418 HSM_M_BUS_SAFETY_ERR
  fields as MSS_CR5A_AXI_RD_BUS_SAFETY_ERR
0x41C HSM_M_BUS_SAFETY_ERR_STAT_DATA0
  fields as MSS_CR5A_AXI_RD_BUS_SAFETY_ERR_STAT_DATA0
0x420 HSM_M_BUS_SAFETY_ERR_STAT_CMD
  fields as MSS_CR5A_AXI_RD_BUS_SAFETY_ERR_STAT_CMD
0x424 HSM_M_BUS_SAFETY_ERR_STAT_WRITE
  fields as MSS_CR5A_AXI_RD_BUS_SAFETY_ERR_STAT_CMD
0x428 HSM_M_BUS_SAFETY_ERR_STAT_READ
  fields as MSS_CR5A_AXI_RD_BUS_SAFETY_ERR_STAT_CMD
0x42C HSM_M_BUS_SAFETY_ERR_STAT_WRITERESP
  fields as MSS_CR5A_AXI_RD_BUS_SAFETY_ERR_STAT_CMD
0x430 HSM_S_BUS_SAFETY_CTRL access per field
  fields as MSS_CR5A_AXI_RD_BUS_SAFETY_CTRL
0x434 HSM_S_BUS_SAFETY_FI rw
  fields as MSS_CR5A_AXI_RD_BUS_SAFETY_FI
0x438 HSM_S_BUS_SAFETY_ERR
  fields as MSS_CR5A_AXI_RD_BUS_SAFETY_ERR
0x43C HSM_S_BUS_SAFETY_ERR_STAT_DATA0
  fields as MSS_CR5A_AXI_RD_BUS_SAFETY_ERR_STAT_DATA0
0x440 HSM_S_BUS_SAFETY_ERR_STAT_CMD
  fields as MSS_CR5A_AXI_RD_BUS_SAFETY_ERR_STAT_CMD
0x444 HSM_S_BUS_SAFETY_ERR_STAT_WRITE
  fields as MSS_CR5A_AXI_RD_BUS_SAFETY_ERR_STAT_CMD
0x448 HSM_S_BUS_SAFETY_ERR_STAT_READ
  fields as MSS_CR5A_AXI_RD_BUS_SAFETY_ERR_STAT_CMD
0x44C HSM_S_BUS_SAFETY_ERR_STAT_WRITERESP
  fields as MSS_CR5A_AXI_RD_BUS_SAFETY_ERR_STAT_CMD
0x450 DAP_R232_BUS_SAFETY_CTRL access per field
  fields as MSS_CR5A_AXI_RD_BUS_SAFETY_CTRL
0x454 DAP_R232_BUS_SAFETY_FI rw
  fields as MSS_CR5A_AXI_RD_BUS_SAFETY_FI
0x458 DAP_R232_BUS_SAFETY_ERR
  fields as MSS_CR5A_AXI_RD_BUS_SAFETY_ERR
0x45C DAP_R232_BUS_SAFETY_ERR_STAT_DATA0
  fields as MSS_CR5A_AXI_RD_BUS_SAFETY_ERR_STAT_DATA0
0x460 DAP_R232_BUS_SAFETY_ERR_STAT_CMD
  fields as MSS_CR5A_AXI_RD_BUS_SAFETY_ERR_STAT_CMD
0x464 DAP_R232_BUS_SAFETY_ERR_STAT_WRITE
  fields as MSS_CR5A_AXI_RD_BUS_SAFETY_ERR_STAT_CMD
0x468 DAP_R232_BUS_SAFETY_ERR_STAT_READ
  fields as MSS_CR5A_AXI_RD_BUS_SAFETY_ERR_STAT_CMD
0x46C DAP_R232_BUS_SAFETY_ERR_STAT_WRITERESP
  fields as MSS_CR5A_AXI_RD_BUS_SAFETY_ERR_STAT_CMD
0x470 MSS_L2_A_BUS_SAFETY_CTRL access per field
  fields as MSS_CR5A_AXI_RD_BUS_SAFETY_CTRL
0x474 MSS_L2_A_BUS_SAFETY_FI rw
  fields as MSS_CR5A_AXI_RD_BUS_SAFETY_FI
0x478 MSS_L2_A_BUS_SAFETY_ERR
  fields as MSS_CR5A_AXI_RD_BUS_SAFETY_ERR
0x47C MSS_L2_A_BUS_SAFETY_ERR_STAT_DATA0
  fields as MSS_CR5A_AXI_RD_BUS_SAFETY_ERR_STAT_DATA0
0x480 MSS_L2_A_BUS_SAFETY_ERR_STAT_CMD
  fields as MSS_CR5A_AXI_RD_BUS_SAFETY_ERR_STAT_CMD
0x484 MSS_L2_A_BUS_SAFETY_ERR_STAT_WRITE
  fields as MSS_CR5A_AXI_RD_BUS_SAFETY_ERR_STAT_CMD
0x488 MSS_L2_A_BUS_SAFETY_ERR_STAT_READ
  fields as MSS_CR5A_AXI_RD_BUS_SAFETY_ERR_STAT_CMD
0x48C MSS_L2_A_BUS_SAFETY_ERR_STAT_WRITERESP
  fields as MSS_CR5A_AXI_RD_BUS_SAFETY_ERR_STAT_CMD
0x490 MSS_L2_B_BUS_SAFETY_CTRL access per field
  fields as MSS_CR5A_AXI_RD_BUS_SAFETY_CTRL
0x494 MSS_L2_B_BUS_SAFETY_FI rw
  fields as MSS_CR5A_AXI_RD_BUS_SAFETY_FI
0x498 MSS_L2_B_BUS_SAFETY_ERR
  fields as MSS_CR5A_AXI_RD_BUS_SAFETY_ERR
0x49C MSS_L2_B_BUS_SAFETY_ERR_STAT_DATA0
  fields as MSS_CR5A_AXI_RD_BUS_SAFETY_ERR_STAT_DATA0
0x4A0 MSS_L2_B_BUS_SAFETY_ERR_STAT_CMD
  fields as MSS_CR5A_AXI_RD_BUS_SAFETY_ERR_STAT_CMD
0x4A4 MSS_L2_B_BUS_SAFETY_ERR_STAT_WRITE
  fields as MSS_CR5A_AXI_RD_BUS_SAFETY_ERR_STAT_CMD
0x4A8 MSS_L2_B_BUS_SAFETY_ERR_STAT_READ
  fields as MSS_CR5A_AXI_RD_BUS_SAFETY_ERR_STAT_CMD
0x4AC MSS_L2_B_BUS_SAFETY_ERR_STAT_WRITERESP
  fields as MSS_CR5A_AXI_RD_BUS_SAFETY_ERR_STAT_CMD
0x4B0 MSS_MBOX_BUS_SAFETY_CTRL access per field
  fields as MSS_CR5A_AXI_RD_BUS_SAFETY_CTRL
0x4B4 MSS_MBOX_BUS_SAFETY_FI rw
  fields as MSS_CR5A_AXI_RD_BUS_SAFETY_FI
0x4B8 MSS_MBOX_BUS_SAFETY_ERR
  fields as MSS_CR5A_AXI_RD_BUS_SAFETY_ERR
0x4BC MSS_MBOX_BUS_SAFETY_ERR_STAT_DATA0
  fields as MSS_CR5A_AXI_RD_BUS_SAFETY_ERR_STAT_DATA0
0x4C0 MSS_MBOX_BUS_SAFETY_ERR_STAT_CMD
  fields as MSS_CR5A_AXI_RD_BUS_SAFETY_ERR_STAT_CMD
0x4C4 MSS_MBOX_BUS_SAFETY_ERR_STAT_WRITE
  fields as MSS_CR5A_AXI_RD_BUS_SAFETY_ERR_STAT_CMD
0x4C8 MSS_MBOX_BUS_SAFETY_ERR_STAT_READ
  fields as MSS_CR5A_AXI_RD_BUS_SAFETY_ERR_STAT_CMD
0x4CC MSS_MBOX_BUS_SAFETY_ERR_STAT_WRITERESP
  fields as MSS_CR5A_AXI_RD_BUS_SAFETY_ERR_STAT_CMD
0x4D0 MSS_SWBUF_BUS_SAFETY_CTRL access per field
  fields as MSS_CR5A_AXI_RD_BUS_SAFETY_CTRL
0x4D4 MSS_SWBUF_BUS_SAFETY_FI rw
  fields as MSS_CR5A_AXI_RD_BUS_SAFETY_FI
0x4D8 MSS_SWBUF_BUS_SAFETY_ERR
  fields as MSS_CR5A_AXI_RD_BUS_SAFETY_ERR
0x4DC MSS_SWBUF_BUS_SAFETY_ERR_STAT_DATA0
  fields as MSS_CR5A_AXI_RD_BUS_SAFETY_ERR_STAT_DATA0
0x4E0 MSS_SWBUF_BUS_SAFETY_ERR_STAT_CMD
  fields as MSS_CR5A_AXI_RD_BUS_SAFETY_ERR_STAT_CMD
0x4E4 MSS_SWBUF_BUS_SAFETY_ERR_STAT_WRITE
  fields as MSS_CR5A_AXI_RD_BUS_SAFETY_ERR_STAT_CMD
0x4E8 MSS_SWBUF_BUS_SAFETY_ERR_STAT_READ
  fields as MSS_CR5A_AXI_RD_BUS_SAFETY_ERR_STAT_CMD
0x4EC MSS_SWBUF_BUS_SAFETY_ERR_STAT_WRITERESP
  fields as MSS_CR5A_AXI_RD_BUS_SAFETY_ERR_STAT_CMD
0x4F0 MSS_GPADC_BUS_SAFETY_CTRL access per field
  fields as MSS_CR5A_AXI_RD_BUS_SAFETY_CTRL
0x4F4 MSS_GPADC_BUS_SAFETY_FI rw
  fields as MSS_CR5A_AXI_RD_BUS_SAFETY_FI
0x4F8 MSS_GPADC_BUS_SAFETY_ERR
  fields as MSS_CR5A_AXI_RD_BUS_SAFETY_ERR
0x4FC MSS_GPADC_BUS_SAFETY_ERR_STAT_DATA0
  fields as MSS_CR5A_AXI_RD_BUS_SAFETY_ERR_STAT_DATA0
0x500 MSS_GPADC_BUS_SAFETY_ERR_STAT_CMD
  fields as MSS_CR5A_AXI_RD_BUS_SAFETY_ERR_STAT_CMD
0x504 MSS_GPADC_BUS_SAFETY_ERR_STAT_WRITE
  fields as MSS_CR5A_AXI_RD_BUS_SAFETY_ERR_STAT_CMD
0x508 MSS_GPADC_BUS_SAFETY_ERR_STAT_READ
  fields as MSS_CR5A_AXI_RD_BUS_SAFETY_ERR_STAT_CMD
0x50C MSS_GPADC_BUS_SAFETY_ERR_STAT_WRITERESP
  fields as MSS_CR5A_AXI_RD_BUS_SAFETY_ERR_STAT_CMD
0x510 MSS_BUS_SAFETY_SEC_ERR_STAT0
  [31] mss_dmmslv — Bus safety single-bit-error of Node mentioned in the field
  [30] mss_dmm — Bus safety single-bit-error of Node mentioned in the field
  [29] gpadc — Bus safety single-bit-error of Node mentioned in the field
  [28] mss_swbuf — Bus safety single-bit-error of Node mentioned in the field
  [27] mss_mbox — Bus safety single-bit-error of Node mentioned in the field
  [26] l2ram1 — Bus safety single-bit-error of Node mentioned in the field
  [25] l2ram0 — Bus safety single-bit-error of Node mentioned in the field
  [24] dthe — Bus safety single-bit-error of Node mentioned in the field
  [23] hsm_s — Bus safety single-bit-error of Node mentioned in the field
  [22] per_pcr2 — Bus safety single-bit-error of Node mentioned in the field
  [21] per_pcr — Bus safety single-bit-error of Node mentioned in the field
  [20] mcrc — Bus safety single-bit-error of Node mentioned in the field
  [19] qspi — Bus safety single-bit-error of Node mentioned in the field
  [18] hsm_tptc_A1_wr — Bus safety single-bit-error of Node mentioned in the field
  [17] hsm_tptc_A1_rd — Bus safety single-bit-error of Node mentioned in the field
  [16] hsm_tptc_A0_wr — Bus safety single-bit-error of Node mentioned in the field
  [15] hsm_tptc_A0_rd — Bus safety single-bit-error of Node mentioned in the field
  [14] mss_tptc_B1_wr — Bus safety single-bit-error of Node mentioned in the field
  [13] mss_tptc_A1_wr — Bus safety single-bit-error of Node mentioned in the field
  [12] mss_tptc_A0_wr — Bus safety single-bit-error of Node mentioned in the field
  [11] mss_tptc_B1_rd — Bus safety single-bit-error of Node mentioned in the field
  [10] mss_tptc_A1_rd — Bus safety single-bit-error of Node mentioned in the field
  [9] mss_tptc_A0_rd — Bus safety single-bit-error of Node mentioned in the field
  [8] cpsw — Bus safety single-bit-error of Node mentioned in the field
  [7] hsm — Bus safety single-bit-error of Node mentioned in the field
  [6] dap_rs232 — Bus safety single-bit-error of Node mentioned in the field
  [5] cr5b_slv — Bus safety single-bit-error of Node mentioned in the field
  [4] cr5a_slv — Bus safety single-bit-error of Node mentioned in the field
  [3] cr5b_wr — Bus safety single-bit-error of Node mentioned in the field
  [2] cr5a_wr — Bus safety single-bit-error of Node mentioned in the field
  [1] cr5b_rd — Bus safety single-bit-error of Node mentioned in the field
  [0] cr5a_rd — Bus safety single-bit-error of Node mentioned in the field
0x514 MSS_BUS_SAFETY_SEC_ERR_STAT1
  [24] mss_to_mdo — Bus safety single-bit-error of Node mentioned in the field
0x518 HW_REG0 rw
  [31:0] hwreg0 — HW reserved Regsiter
0x51C HW_REG1 rw
  [31:0] hwreg1 — HW reserved Regsiter
0x520 PREVIOUS_NAME rw
  [31:0] hwreg2 — HW reserved Regsiter
{0x518+4i} HW_REG{i} rw (i=3..7)
  [31:0] hwreg{i} — HW reserved Regsiter
0x538 MSS_DMM_BUS_SAFETY_CTRL access per field
  fields as MSS_CR5A_AXI_RD_BUS_SAFETY_CTRL
0x53C MSS_DMM_BUS_SAFETY_FI rw
  fields as MSS_CR5A_AXI_RD_BUS_SAFETY_FI
0x540 MSS_DMM_BUS_SAFETY_ERR
  fields as MSS_CR5A_AXI_RD_BUS_SAFETY_ERR
0x544 MSS_DMM_BUS_SAFETY_ERR_STAT_DATA0
  fields as MSS_CR5A_AXI_RD_BUS_SAFETY_ERR_STAT_DATA0
0x548 MSS_DMM_BUS_SAFETY_ERR_STAT_CMD
  fields as MSS_CR5A_AXI_RD_BUS_SAFETY_ERR_STAT_CMD
0x54C MSS_DMM_BUS_SAFETY_ERR_STAT_WRITE
  fields as MSS_CR5A_AXI_RD_BUS_SAFETY_ERR_STAT_CMD
0x550 MSS_DMM_BUS_SAFETY_ERR_STAT_READ
  fields as MSS_CR5A_AXI_RD_BUS_SAFETY_ERR_STAT_CMD
0x554 MSS_DMM_BUS_SAFETY_ERR_STAT_WRITERESP
  fields as MSS_CR5A_AXI_RD_BUS_SAFETY_ERR_STAT_CMD
0x558 MSS_DMM_SLV_BUS_SAFETY_CTRL access per field
  fields as MSS_CR5A_AXI_RD_BUS_SAFETY_CTRL
0x55C MSS_DMM_SLV_BUS_SAFETY_FI rw
  fields as MSS_CR5A_AXI_RD_BUS_SAFETY_FI
0x560 MSS_DMM_SLV_BUS_SAFETY_ERR
  fields as MSS_CR5A_AXI_RD_BUS_SAFETY_ERR
0x564 MSS_DMM_SLV_BUS_SAFETY_ERR_STAT_DATA0
  fields as MSS_CR5A_AXI_RD_BUS_SAFETY_ERR_STAT_DATA0
0x568 MSS_DMM_SLV_BUS_SAFETY_ERR_STAT_CMD
  fields as MSS_CR5A_AXI_RD_BUS_SAFETY_ERR_STAT_CMD
0x56C MSS_DMM_SLV_BUS_SAFETY_ERR_STAT_WRITE
  fields as MSS_CR5A_AXI_RD_BUS_SAFETY_ERR_STAT_CMD
0x570 MSS_DMM_SLV_BUS_SAFETY_ERR_STAT_READ
  fields as MSS_CR5A_AXI_RD_BUS_SAFETY_ERR_STAT_CMD
0x574 MSS_DMM_SLV_BUS_SAFETY_ERR_STAT_WRITERESP
  fields as MSS_CR5A_AXI_RD_BUS_SAFETY_ERR_STAT_CMD
0x578 MSS_TO_MDO_BUS_SAFETY_CTRL access per field
  fields as MSS_CR5A_AXI_RD_BUS_SAFETY_CTRL
0x57C MSS_TO_MDO_BUS_SAFETY_FI rw
  fields as MSS_CR5A_AXI_RD_BUS_SAFETY_FI
0x580 MSS_TO_MDO_BUS_SAFETY_ERR
  fields as MSS_CR5A_AXI_RD_BUS_SAFETY_ERR
0x584 MSS_TO_MDO_BUS_SAFETY_ERR_STAT_DATA0
  fields as MSS_CR5A_AXI_RD_BUS_SAFETY_ERR_STAT_DATA0
0x588 MSS_TO_MDO_BUS_SAFETY_ERR_STAT_CMD
  fields as MSS_CR5A_AXI_RD_BUS_SAFETY_ERR_STAT_CMD
0x58C MSS_TO_MDO_BUS_SAFETY_ERR_STAT_WRITE
  fields as MSS_CR5A_AXI_RD_BUS_SAFETY_ERR_STAT_CMD
0x590 MSS_TO_MDO_BUS_SAFETY_ERR_STAT_READ
  fields as MSS_CR5A_AXI_RD_BUS_SAFETY_ERR_STAT_CMD
0x594 MSS_TO_MDO_BUS_SAFETY_ERR_STAT_WRITERESP
  fields as MSS_CR5A_AXI_RD_BUS_SAFETY_ERR_STAT_CMD
0x598 MSS_SCRP_BUS_SAFETY_CTRL access per field
  fields as MSS_CR5A_AXI_RD_BUS_SAFETY_CTRL
0x59C MSS_SCRP_BUS_SAFETY_FI rw
  fields as MSS_CR5A_AXI_RD_BUS_SAFETY_FI
0x5A0 MSS_SCRP_BUS_SAFETY_ERR
  fields as MSS_CR5A_AXI_RD_BUS_SAFETY_ERR
0x5A4 MSS_SCRP_BUS_SAFETY_ERR_STAT_DATA0
  fields as MSS_CR5A_AXI_RD_BUS_SAFETY_ERR_STAT_DATA0
0x5A8 MSS_SCRP_BUS_SAFETY_ERR_STAT_CMD
  fields as MSS_CR5A_AXI_RD_BUS_SAFETY_ERR_STAT_CMD
0x5AC MSS_SCRP_BUS_SAFETY_ERR_STAT_WRITE
  fields as MSS_CR5A_AXI_RD_BUS_SAFETY_ERR_STAT_CMD
0x5B0 MSS_SCRP_BUS_SAFETY_ERR_STAT_READ
  fields as MSS_CR5A_AXI_RD_BUS_SAFETY_ERR_STAT_CMD
0x5B4 MSS_SCRP_BUS_SAFETY_ERR_STAT_WRITERESP
  fields as MSS_CR5A_AXI_RD_BUS_SAFETY_ERR_STAT_CMD
0x5B8 MSS_CR5A_AHB_BUS_SAFETY_CTRL access per field
  fields as MSS_CR5A_AXI_RD_BUS_SAFETY_CTRL
0x5BC MSS_CR5A_AHB_BUS_SAFETY_FI rw
  fields as MSS_CR5A_AXI_RD_BUS_SAFETY_FI
0x5C0 MSS_CR5A_AHB_BUS_SAFETY_ERR
  fields as MSS_CR5A_AXI_RD_BUS_SAFETY_ERR
0x5C4 MSS_CR5A_AHB_BUS_SAFETY_ERR_STAT_DATA0
  fields as MSS_CR5A_AXI_RD_BUS_SAFETY_ERR_STAT_DATA0
0x5C8 MSS_CR5A_AHB_BUS_SAFETY_ERR_STAT_CMD
  fields as MSS_CR5A_AXI_RD_BUS_SAFETY_ERR_STAT_CMD
0x5CC MSS_CR5A_AHB_BUS_SAFETY_ERR_STAT_WRITE
  fields as MSS_CR5A_AXI_RD_BUS_SAFETY_ERR_STAT_CMD
0x5D0 MSS_CR5A_AHB_BUS_SAFETY_ERR_STAT_READ
  fields as MSS_CR5A_AXI_RD_BUS_SAFETY_ERR_STAT_CMD
0x5D4 MSS_CR5A_AHB_BUS_SAFETY_ERR_STAT_WRITERESP
  fields as MSS_CR5A_AXI_RD_BUS_SAFETY_ERR_STAT_CMD
0x5D8 MSS_CR5B_AHB_BUS_SAFETY_CTRL access per field
  fields as MSS_CR5A_AXI_RD_BUS_SAFETY_CTRL
0x5DC MSS_CR5B_AHB_BUS_SAFETY_FI rw
  fields as MSS_CR5A_AXI_RD_BUS_SAFETY_FI
0x5E0 MSS_CR5B_AHB_BUS_SAFETY_ERR
  fields as MSS_CR5A_AXI_RD_BUS_SAFETY_ERR
0x5E4 MSS_CR5B_AHB_BUS_SAFETY_ERR_STAT_DATA0
  fields as MSS_CR5A_AXI_RD_BUS_SAFETY_ERR_STAT_DATA0
0x5E8 MSS_CR5B_AHB_BUS_SAFETY_ERR_STAT_CMD
  fields as MSS_CR5A_AXI_RD_BUS_SAFETY_ERR_STAT_CMD
0x5EC MSS_CR5B_AHB_BUS_SAFETY_ERR_STAT_WRITE
  fields as MSS_CR5A_AXI_RD_BUS_SAFETY_ERR_STAT_CMD
0x5F0 MSS_CR5B_AHB_BUS_SAFETY_ERR_STAT_READ
  fields as MSS_CR5A_AXI_RD_BUS_SAFETY_ERR_STAT_CMD
0x5F4 MSS_CR5B_AHB_BUS_SAFETY_ERR_STAT_WRITERESP
  fields as MSS_CR5A_AXI_RD_BUS_SAFETY_ERR_STAT_CMD
0x5F8 DMM_CTRL_REG rw
  [0] dmm_pad_select — 0: SOC will be able to send the packet to DMMA/B 1: PAD will be able to send the packet to DMMA/B controlling from PAD
0x5FC MSS_CR5A_MBOX_WRITE_DONE rw
  [4n] proc_{n} (n=0..7) — This register should be written once finishing writing into the mailbox memory of processor {n}
0x600 MSS_CR5A_MBOX_READ_REQ rw
  [4n] proc_{n} (n=0..7) — This is request from processor {n} to mss_cr5a. Requesting it to read from mailbox.
0x604 MSS_CR5A_MBOX_READ_DONE rw
  [4n] proc_{n} (n=0..7) — This register should be written once finishing reading from CR5A's mailbox written by proc {n}
0x608 MSS_CR5B_MBOX_WRITE_DONE rw
  fields as MSS_CR5A_MBOX_WRITE_DONE
0x60C MSS_CR5B_MBOX_READ_REQ rw
  [4n] proc_{n} (n=0..7) — This is request from processor {n} to mss_CR5B. Requesting it to read from mailbox.
0x610 MSS_CR5B_MBOX_READ_DONE rw
  [4n] proc_{n} (n=0..7) — This register should be written once finishing reading from CR5B's mailbox written by proc {n}
0x614 MSS_PBIST_KEY_RST rw
  [7:4] pbist_st_rst — MSS PBIST controller will be brought out of reset when value is 0xA
  [3:0] pbist_st_key — Top PBIST Selftest Key. Valid value is 0x5
{0x618+4i} MSS_PBIST_REG{i} rw (i=0..2)
  [31:0] pbist_reg
0x624 MSS_QSPI_CONFIG rw
  [10:8] clk_loopback — Write 3'b111 to take board level loop back clock for QSPI
  [2:0] ext_clk — Write 3'b111 to external clock as QSPI baud clock source needed for DFT IO char.
0x628 MSS_STC_CONTROL rw
  [2:0] cr5_wfi_overide — writing 3'b111 will bypass the wfi signals from R5SS.
0x62C MSS_CTI_TRIG_SEL rw
  [7:0] trig8_sel — Used for selecting the trigger source for 8th trigger of MSS_CTI
0x630 MSS_DBGSS_CTI_TRIG_SEL rw
  [23:16] trig3 — Used for selecting the trigger source for 3rd trigger of ONE_MCU_CTI
  [15:8] trig2 — Used for selecting the trigger source for 2nd trigger of ONE_MCU_CTI
  [7:0] trig1 — Used for selecting the trigger source for 1st trigger of ONE_MCU_CTI
{0x634+4i} MSS_BOOT_INFO_REG{i} rw (i=0..7)
  [31:0] config — Reserved Register for Software use
0x654 MSS_TPTC_ECCAGGR_CLK_CNTRL rw
  [2] tptc_B0 — Writing '0' will gate the clock to TPTC_B0-FIFO during ECC-AGGR interaction(fault injection)
  [1] tptc_A1 — Writing '0' will gate the clock to TPTC_A1-FIFO during ECC-AGGR interaction(fault injection)
  [0] tptc_A0 — Writing '0' will gate the clock to TPTC_A0-FIFO during ECC-AGGR interaction(fault injection)
